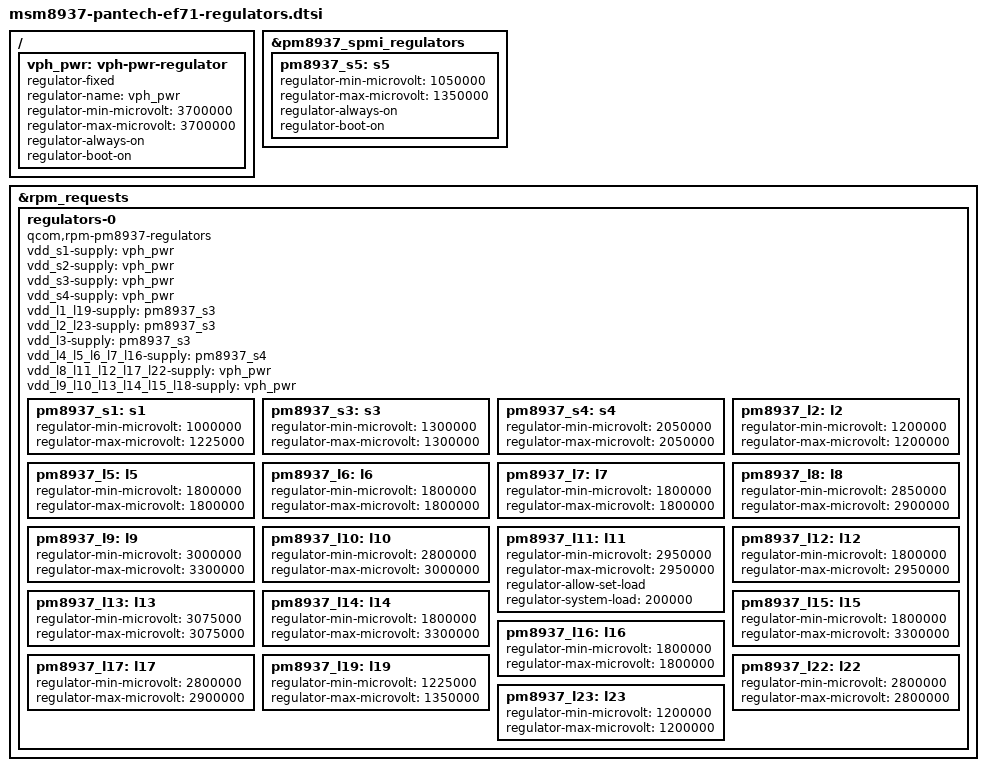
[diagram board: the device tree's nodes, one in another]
// SPDX-License-Identifier: GPL-2.0-only
/*
 * EF71 regulators: VPH_PWR, the PM8937 SPMI (APC) and RPM regulators,
 * and the PMI8950 haptics driving the vibrator.
 *
 * Copyright (c) 2026, hiru <rlawoehd187@naver.com>
 */

#include <dt-bindings/input/qcom,spmi-haptics.h>

/ {
	vph_pwr: vph-pwr-regulator {
		compatible = "regulator-fixed";
		regulator-name = "vph_pwr";
		regulator-min-microvolt = <3700000>;
		regulator-max-microvolt = <3700000>;
		regulator-always-on;
		regulator-boot-on;
	};
};

&pm8937_spmi_regulators {
	/* APC */
	pm8937_s5: s5 {
		regulator-min-microvolt = <1050000>;
		regulator-max-microvolt = <1350000>;
		regulator-always-on;
		regulator-boot-on;
	};
};

&rpm_requests {
	regulators-0 {
		compatible = "qcom,rpm-pm8937-regulators";

		vdd_s1-supply = <&vph_pwr>;
		vdd_s2-supply = <&vph_pwr>;
		vdd_s3-supply = <&vph_pwr>;
		vdd_s4-supply = <&vph_pwr>;

		vdd_l1_l19-supply = <&pm8937_s3>;
		vdd_l2_l23-supply = <&pm8937_s3>;
		vdd_l3-supply = <&pm8937_s3>;
		vdd_l4_l5_l6_l7_l16-supply = <&pm8937_s4>;
		vdd_l8_l11_l12_l17_l22-supply = <&vph_pwr>;
		vdd_l9_l10_l13_l14_l15_l18-supply = <&vph_pwr>;

		pm8937_s1: s1 {
			regulator-min-microvolt = <1000000>;
			regulator-max-microvolt = <1225000>;
		};

		pm8937_s3: s3 {
			regulator-min-microvolt = <1300000>;
			regulator-max-microvolt = <1300000>;
		};

		pm8937_s4: s4 {
			regulator-min-microvolt = <2050000>;
			regulator-max-microvolt = <2050000>;
		};

		pm8937_l2: l2 {
			regulator-min-microvolt = <1200000>;
			regulator-max-microvolt = <1200000>;
		};

		pm8937_l5: l5 {
			regulator-min-microvolt = <1800000>;
			regulator-max-microvolt = <1800000>;
		};

		pm8937_l6: l6 {
			regulator-min-microvolt = <1800000>;
			regulator-max-microvolt = <1800000>;
		};

		pm8937_l7: l7 {
			regulator-min-microvolt = <1800000>;
			regulator-max-microvolt = <1800000>;
		};

		pm8937_l8: l8 {
			regulator-min-microvolt = <2850000>;
			regulator-max-microvolt = <2900000>;
		};

		pm8937_l9: l9 {
			regulator-min-microvolt = <3000000>;
			regulator-max-microvolt = <3300000>;
		};

		pm8937_l10: l10 {
			regulator-min-microvolt = <2800000>;
			regulator-max-microvolt = <3000000>;
		};

		pm8937_l11: l11 {
			regulator-min-microvolt = <2950000>;
			regulator-max-microvolt = <2950000>;
			regulator-allow-set-load;
			regulator-system-load = <200000>;
		};

		pm8937_l12: l12 {
			regulator-min-microvolt = <1800000>;
			regulator-max-microvolt = <2950000>;
		};

		pm8937_l13: l13 {
			regulator-min-microvolt = <3075000>;
			regulator-max-microvolt = <3075000>;
		};

		pm8937_l14: l14 {
			regulator-min-microvolt = <1800000>;
			regulator-max-microvolt = <3300000>;
		};

		pm8937_l15: l15 {
			regulator-min-microvolt = <1800000>;
			regulator-max-microvolt = <3300000>;
		};

		pm8937_l16: l16 {
			regulator-min-microvolt = <1800000>;
			regulator-max-microvolt = <1800000>;
		};

		pm8937_l17: l17 {
			regulator-min-microvolt = <2800000>;
			regulator-max-microvolt = <2900000>;
		};

		pm8937_l19: l19 {
			regulator-min-microvolt = <1225000>;
			regulator-max-microvolt = <1350000>;
		};

		pm8937_l22: l22 {
			regulator-min-microvolt = <2800000>;
			regulator-max-microvolt = <2800000>;
		};

		pm8937_l23: l23 {
			regulator-min-microvolt = <1200000>;
			regulator-max-microvolt = <1200000>;
		};
	};
};
